# SAMA7D65D4GN8 register map
Vendor: Microchip Technology; Series: SAMA7D6; File version: 0
Registers are 32-bit, read-write, reset 0x0 unless marked. A register's access mark holds for its fields unless they carry their own. Offsets are from the block's base; [hi:lo] are bit positions; {n}, {i} and the like mark numbered series.

## PUF — Physical Unclonable Functions
Base 0xE0024000
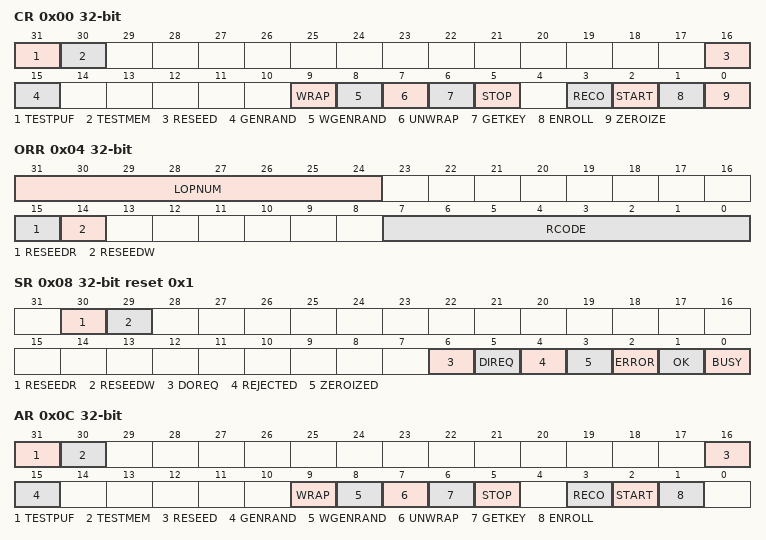
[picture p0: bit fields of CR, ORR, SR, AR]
0x00 CR — Control Register
  [31] TESTPUF — Test PUF Operation
  [30] TESTMEM — Test Memory Operation
  [16] RESEED — Reseed Operation
  [15] GENRAND — Generate Random Operation
  [9] WRAP — Wrap Operation
  [8] WGENRAND — Wrap Generated Random Operation
  [7] UNWRAP — Unwrap Operation
  [6] GETKEY — Get Key Operation
  [5] STOP — Stop Operation
  [3] RECO — Reconstruct Operation
  [2] START — Start Operation
  [1] ENROLL — Enroll Operation
  [0] ZEROIZE — Zeroize Operation
0x04 ORR ro — Operation Result Register
  [31:24] LOPNUM — Last Operation Number
    0=IID_PUF_LO_PROGRESS (An operation is in progress.); 1=IID_PUF_LO_ENROLL (The last operation was ENROLL.); 2=IID_PUF_LO_START (The last operation was START.); 3=IID_PUF_LO_RECONSTRUCT (The last operation was RECONSTRUCT.); 5=IID_PUF_LO_STOP (The last operation was STOP.); 6=IID_PUF_LO_GET_KEY (The last operation was GET KEY.); 7=IID_PUF_LO_UNWRAP (The last operation was UNWRAP.); 8=IID_PUF_LO_WRAP_GEN_RND (The last operation was WRAP GENERATED RANDOM.); 9=IID_PUF_LO_WRAP (The last operation was WRAP.); 15=IID_PUF_LO_GEN_RND (The last operation was GENERATED RANDOM.); 16=IID_PUF_LO_RESEED (The last operation was RESEED.); 30=IID_PUF_LO_TEST_MEMORY (The last operation was TESTMEMORY.); 31=IID_PUF_LO_TEST_PUF (The last operation was TESTPUF.); 32=IID_PUF_LO_INITIALIZATION (The last operation was INITIALIZATION.); 47=IID_PUF_LO_ZEROIZE (The last operation was ZEROIZE.)
  [15] RESEEDR — Reseed Required
    0=NO_ACTION (No action required.); 1=REQUIRED_ACTION (The maximum number of DRBG2 requests has been done. A reseed must be performed before other operations can be done. This bit is the same as in PUF_SR.)
  [14] RESEEDW — Reseed Warning
    0=NO_ACTION (No action required.); 1=RECOMMENDED_ACTION (The DRBG reseed counter is close to its limit, it is recommended to reseed at the first suitable moment. This bit is the same as in PUF_SR.)
  [7:0] RCODE — Last Operation Result Code
    0=IID_PUF_OK (The last operation was successful or an operation is in progress.); 240=IID_PUF_ERR_PRODUCT (The provided activation code is not correct.); 241=IID_PUF_ERR_PRODUCT_PH2 (The activation code in the second phase is not correct.); 242=IID_PUF_ERR_TRANSFER (The provided activation code is corrupted.); 243=IID_PUF_ERR_TRANSFER_PH2 (The activation code in the second phase is corrupted.); 244=IID_PUF_ERR_AUTH (Authentication of the provided activation code failed.); 245=IID_PUF_ERR_AUTH_PH2 (Authentication of the provided activation code failed in the second phase.); 246=IID_PUF_ERR_PUF_QUALITY (Dedicated Embedded Static RAM PUF quality verification fails.); 247=IID_PUF_ERR_CONTEXT (An incorrect or unsupported context is provided.); 248=IID_PUF_ERR_DESTINATION (A data destination that was set is not allowed according to other settings and the current PUF state.); 251=IID_PUF_FAILURE_DRBG2_ENTROPY (DRBG2 Reseed or Instantiation failed (DRBG1 cannot provide entropy).); 252=IID_PUF_FAILURE_DRBG1_ENTROPY (The entropy test for DRBG1 failed.); 253=IID_PUF_FAILURE_DRBG_HEALTH (One or more of the DRBG health tests failed.); 254=IID_PUF_FAILURE_SETTINGS (Initialization cannot finish due to illegal values in PUF_HW_SETTINGS.); 255=IID_PUF_FAILURE_SRAM (PUF SRAM access has failed.)
0x08 SR reset 0x1 — Status Register
  [30] RESEEDR — Reseed Required
    0=NO_ACTION (No action required.); 1=REQUIRED_ACTION (The maximum number of DRBG2 requests has been done. A reseed must be performed before other operations can be done. This bit is the same as in PUF_ORR.)
  [29] RESEEDW — Reseed Warning
    0=NO_ACTION (No action required.); 1=RECOMMENDED_ACTION (The reseed counter of the DRBG is close to its limit, it is recommended to reseed at the first suitable moment. This bit is the same as in PUF_ORR.)
  [6] DOREQ — Data Out Request Status
    0=No data-out transfer is in progress; 1=A data-out transfer is in progress following a request via PUF_DOR
  [5] DIREQ — Data In Request Status
    0=No data-in transfer is in progress; 1=A data-in transfer is in progress following a request via PUF_DIR
  [4] REJECTED — Last Command Rejection Status (cleared by writing a 1)
    0=No rejection event occurred since the last clearing access; 1=A rejection event occurred when the last command has been launched. Cleared by writing a 1.
  [3] ZEROIZED — PUF Zeroization in Progress
    0=No zeroization is in progress; 1=A zeroization action is in progress or the PUF is in Locked state
  [2] ERROR — Last Operation Failed
    0=The last operation completed successfully; 1=The last operation failed
  [1] OK — Last Operation Successfully Achieved
    0=ERROR bit must be checked; 1=The last operation completed successfully
  [0] BUSY — Operation in Progress
    0=No operation is in progress. A new operation can be initiated.; 1=An operation is in progress. No new operation must be launched.
0x0C AR ro — Allow Register
  [31] TESTPUF — Test PUF Operation
  [30] TESTMEM — Test Memory Operation
  [16] RESEED — Reseed Operation
  [15] GENRAND — Generate Random Operation
  [9] WRAP — Wrap Operation
  [8] WGENRAND — Wrap Generated Random Operation
  [7] UNWRAP — Unwrap Operation
  [6] GETKEY — Get Key Operation
  [5] STOP — Stop Operation
  [3] RECO — Reconstruct Operation
  [2] START — Start Operation
  [1] ENROLL — Enroll Operation
0x10 IER — Interrupt Enable Register
  [0] INTEN — Interruption Enable
    0=Disables the interruption; 1=Enables the PUF to trigger an interruption from the sources selected in PUF_IMR
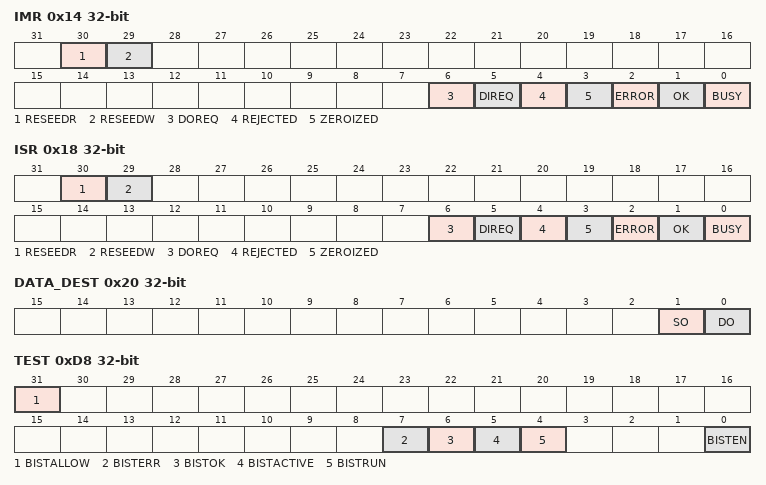
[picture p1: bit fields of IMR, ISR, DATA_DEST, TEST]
0x14 IMR — Interrupt Mask Register
  [30] RESEEDR — Reseed Action Required Event
  [29] RESEEDW — Reseed Warning Event
  [6] DOREQ — Data Out Request Event
  [5] DIREQ — Data In Request Event
  [4] REJECTED — Last Activation Code Rejection Event
  [3] ZEROIZED — Zeroized Operation Completed Event
  [2] ERROR — Last Operation Fail Event
  [1] OK — Last Operation Successful Achievement Event
  [0] BUSY — Operation Start Event
0x18 ISR — Interrupt Status Register
  [30] RESEEDR — Reseed Action Required (cleared by writing a 1)
  [29] RESEEDW — Reseed Warning (cleared by writing a 1)
  [6] DOREQ — Data Out Request (cleared by writing a 1)
  [5] DIREQ — Data In Request (cleared by writing a 1)
  [4] REJECTED — Last Activation Code Rejection (cleared by writing a 1)
  [3] ZEROIZED — Zeroized Operation Completed (cleared by writing a 1)
  [2] ERROR — Last Operation Fail (cleared by writing a 1)
  [1] OK — Last Operation Achievement (cleared by writing a 1)
  [0] BUSY — Operation in Progress (cleared by writing a 1)
0x20 DATA_DEST — Data Destination Register
  [1] SO — Data Output on Private Key Bus
    0=DISABLED (Private Key Bus cannot transfer PUF data.); 1=VIA_KEYBUS (Private Key Bus is enabled to transfer PUF data.)
  [0] DO — Data Output on PUF_DOR
    0=DISABLED (PUF_DOR cannot be used to read data from PUF operations.); 1=DO_VIA_DOR (PUF_DOR is enabled to read data from PUF operations.)
0x24 DATA_SRC — Data Source Register
  [0] DI — Data Input Loaded from PUF_DIR
    0=DISABLED (PUF_DIR cannot be used to transfer data to PUF.); 1=DI_VIA_DIR (PUF_DIR is enabled to load data to PUF.)
0x28 KEY_INDEX ro
  [3:0] KI — Key Index
0xA0 DIR wo — Data Input Register
  [31:0] DI — Data Input Value
0xA8 DOR ro — Data Output Register
  [31:0] DO — Data Output Value
0xC0 MISC reset 0x1 — Miscellaneous Register
  [0] DEND — Data Endianness
    0=LITTLE (Little-endian mode.); 1=BIG (Big-endian mode. This is the default value.)
0xD0 IF_SR — Interface Status Register
  [0] BUSERR — Bus Access Error (cleared by writing a 1)
    0=NONE (No incorrect access performed since the last write access (BUSERR=1).); 1=ERROR (An incorrect access has been performed. Cleared by writing a 1.)
0xD8 TEST
  [31] BISTALLOW — Built-In Self-Test Allowed
    0=BIST Start (BISTEN) command is disabled and has no effect; 1=BIST Start command (BISTEN) is allowed
  [7] BISTERR — Built-In Self-Test Error
    0=No action; 1=If BISTRUN=1 and BISTACTIVE=0, BIST has failed
  [6] BISTOK — Built-In Self-Test Run Passed
    0=No action; 1=If BISTRUN=1 and BISTACTIVE=0, BIST has passed successfully
  [5] BISTACTIVE — Built-In Self-Test Activity Status
    0=BIST has completed if BISTRUN=1; 1=If BISTRUN=1, BIST is in progress
  [4] BISTRUN — Built-In Self-Test Run Status
    0=BIST is not active or has not started yet; 1=BIST is enabled
  [0] BISTEN — Built-In Self-Test Enable
    0=Disables the BIST, must be performed once BIST completion event occurred (BISTOK=1); 1=Starts the BIST
0xDC PSR ro reset 0xF — Score Register
  [3:0] SCORE — Last Test Score
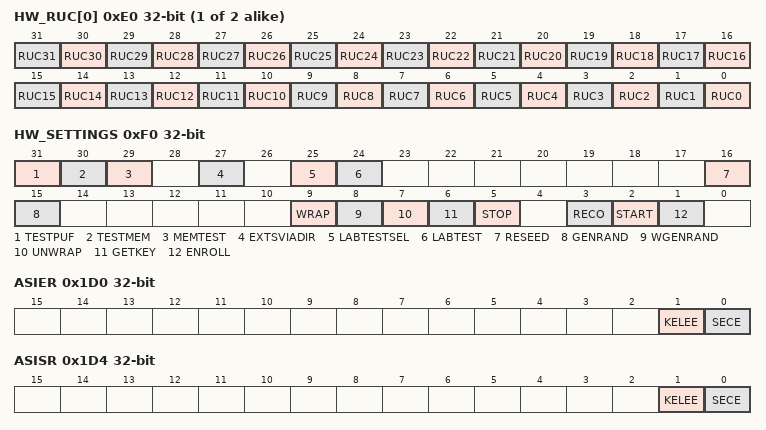
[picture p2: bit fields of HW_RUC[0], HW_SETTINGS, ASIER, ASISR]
{0xE0+4i} HW_RUC[{i}] (i=0..1) ro — Hardware Restrict User Context x Register
  [all] fields
    0=This bit can be used in the user context 0 field; 1=This bit cannot be used in the user context 0 field
  [n] RUC{n} (n=0..31) — Restrict User Context Bit {n}
0xF0 HW_SETTINGS ro — Hardware Settings Register
  [31] TESTPUF — Test PUF Operation
  [30] TESTMEM — Test Memory Operation
  [29] MEMTEST — Memory Tests Included in Initialization
  [27] EXTSVIADIR — External Entropy Required via PUF_DIR During Reseed Operation
  [25] LABTESTSEL — Selection of Lab Test Mode, when LABTEST=0
  [24] LABTEST — Initialization to Lab Test Mode
  [16] RESEED — Reseed Operation
  [15] GENRAND — Generate Random Operation
  [9] WRAP — Wrap Operation
  [8] WGENRAND — Wrap Generated Random Operation
  [7] UNWRAP — Unwrap Operation
  [6] GETKEY — Get Key Operation
  [5] STOP — Stop Operation
  [3] RECO — Reconstruct Operation
  [2] START — Start Operation
  [1] ENROLL — Enroll Operation
0x1D0 ASIER — Access Security Interrupt Enable Register
  [1] KELEE — Key Length Error Interrupt Enable
    0=Disables triggering of the interrupt line on key length error detection; 1=Enables triggering of the interrupt line on key length error detection
  [0] SECE — Security Error Interrupt Enable
    0=Disables triggering of the interrupt line on incorrect/abnormal access to the PUF user interface; 1=Enables triggering of the interrupt line on incorrect/abnormal access to the PUF user interface
0x1D4 ASISR ro — Access Security Interrupt Status Register
  [1] KELEE — Key Length Error
    0=The length of the key corresponds to the expected value; 1=The length of the key does not correspond to the expected value
  [0] SECE — Access Security Error Interrupt Enable
    0=Disables triggering of the interrupt line on incorrect/abnormal access to user interface; 1=Enables triggering of the interrupt line on incorrect/abnormal access to user interface
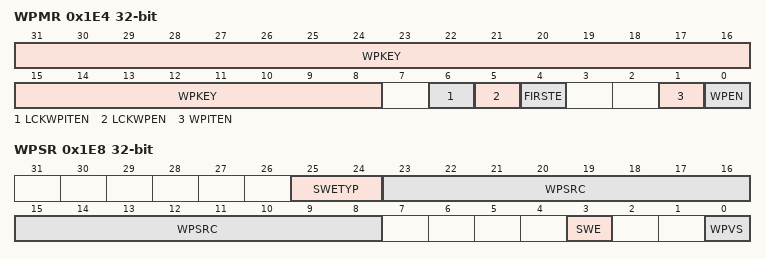
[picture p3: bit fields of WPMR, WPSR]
0x1E4 WPMR — Write Protection Mode Register
  [31:8] WPKEY — Write Protection Key
    0x505546=PASSWD (Writing any other value in this field aborts the write operation. Always reads as 0.)
  [6] LCKWPITEN — Write Protection Lock Enable for Interrupt Register
    0=No effect; 1=Locks the write access to the WPITEN bit until the next system reset. WPITEN must be set in the same access to perform the action.
  [5] LCKWPEN — Write Protection Lock Enable for Configuration Register
    0=No effect; 1=Locks the write access to the WPEN bit until the next system reset. WPEN must be set in the same access to perform the action.
  [4] FIRSTE — First Error Report Enable
    0=The last write protection violation source is reported in PUF_WPSR.WPSRC and the last software control error type is reported in PUF_WPSR.SWETYP. The PUF_ISR.SECE flag is set at the first error occurrence within a series.; 1=Only the first write protection violation source is reported in PUF_WPSR.WPSRC and only the first software control error type is reported in PUF_WPSR.SWETYP. The PUF_ISR.SECE flag is set at the first error occurrence within a series.
  [1] WPITEN — Write Protection Enable for Interrupt
    0=Disables the write protection on interrupt registers if WPKEY corresponds to 0x505546 ('PUF' in ASCII); 1=Enables the write protection on interrupt registers if WPKEY corresponds to 0x505546 ('PUF' in ASCII)
  [0] WPEN — Write Protection Configuration Enable
    0=Disables the write protection if WPKEY corresponds to 0x505546 ('PUF' in ASCII); 1=Enables the write protection if WPKEY corresponds to 0x505546 ('PUF' in ASCII)
0x1E8 WPSR ro — Write Protection Status Register
  [25:24] SWETYP — Software Error Type (cleared on read)
    0=READ_WO (A write-only register has been read.); 1=WRITE_RO (A write access has been performed on a read-only register.); 2=UNDEF_RW (Access to an undefined address.); 3=BAD_DXR (Unexpected access to PUF_DIR/PUF_DOR.)
  [23:8] WPSRC — Write Protection Source
  [3] SWE — Software Control Error (cleared on read)
    0=No software error has occurred since the last read of PUF_WPSR; 1=A software error has occurred since the last read of PUF_WPSR. The field SWETYP details the type of error. The associated incorrect software access is reported in the field WPSRC (if WPVS=0).
  [0] WPVS — Write Protection Violation Status (cleared on read)
    0=No write protection violation has occurred since the last read of PUF_WPSR; 1=Violation of a write protection (PUF_WPMR.WPEN=1 or WPITEN=1) has occurred since the last read of PUF_WPSR
